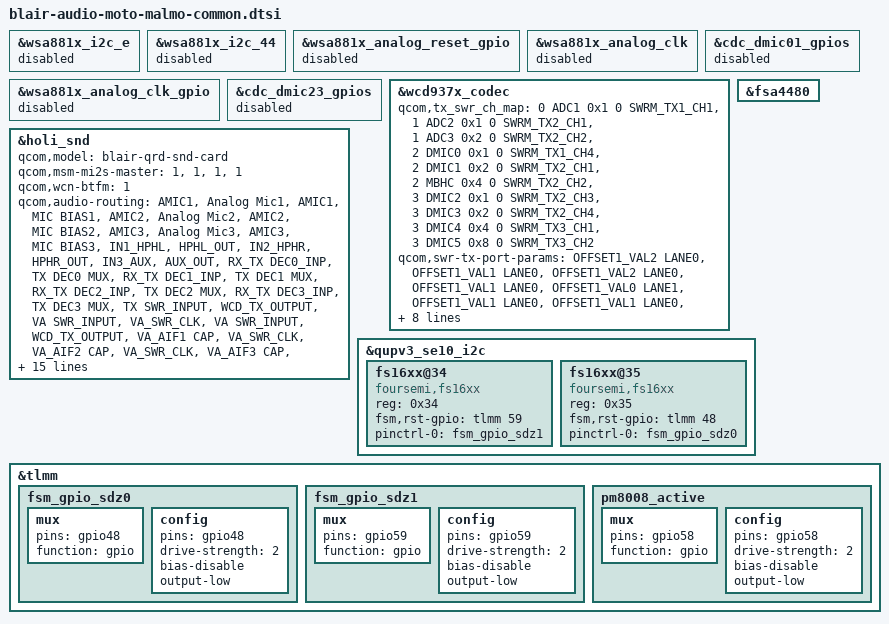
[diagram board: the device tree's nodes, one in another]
/* This is original from blair-audio-qrd.dtsi */
#include "blair-audio-overlay.dtsi"

&wsa881x_i2c_e {
	status = "disabled";
};

&wsa881x_i2c_44 {
	status = "disabled";
};

&wsa881x_analog_reset_gpio {
	status = "disabled";
};

&wsa881x_analog_clk {
	status = "disabled";
};

&wsa881x_analog_clk_gpio {
	status = "disabled";
};

&cdc_dmic01_gpios {
	status = "disabled";
};

&cdc_dmic23_gpios {
	status = "disabled";
};

&wcd937x_codec {
	qcom,tx_swr_ch_map = <0 ADC1 0x1 0 SWRM_TX1_CH1>,
			<1 ADC2 0x1 0 SWRM_TX2_CH1>,
			<1 ADC3 0x2 0 SWRM_TX2_CH2>,
			<2 DMIC0 0x1 0 SWRM_TX1_CH4>,
			<2 DMIC1 0x2 0 SWRM_TX2_CH1>,
			<2 MBHC 0x4 0 SWRM_TX2_CH2>,
			<3 DMIC2 0x1 0 SWRM_TX2_CH3>,
			<3 DMIC3 0x2 0 SWRM_TX2_CH4>,
			<3 DMIC4 0x4 0 SWRM_TX3_CH1>,
			<3 DMIC5 0x8 0 SWRM_TX3_CH2>;
	qcom,swr-tx-port-params =
			<OFFSET1_VAL2 LANE0>, <OFFSET1_VAL1 LANE0>, <OFFSET1_VAL2 LANE0>, <OFFSET1_VAL1 LANE0>,
			<OFFSET1_VAL0 LANE1>, <OFFSET1_VAL1 LANE0>, <OFFSET1_VAL1 LANE0>, <OFFSET1_VAL1 LANE0>,
			<OFFSET1_VAL0 LANE1>, <OFFSET1_VAL2 LANE0>, <OFFSET1_VAL1 LANE0>, <OFFSET1_VAL2 LANE0>,
			<OFFSET1_VAL1 LANE0>, <OFFSET1_VAL1 LANE0>, <OFFSET1_VAL1 LANE0>, <OFFSET1_VAL1 LANE0>;
	qcom,cdc-micbias1-mv = <2500>;
	qcom,cdc-micbias2-mv = <2700>;
	qcom,cdc-micbias3-mv = <2500>;
};

&holi_snd {
	qcom,model = "blair-qrd-snd-card";
	qcom,msm-mi2s-master = <1>, <1>, <1>, <1>;
	qcom,wcn-btfm = <1>;
	qcom,audio-routing =
		"AMIC1", "Analog Mic1",
		"AMIC1", "MIC BIAS1",
		"AMIC2", "Analog Mic2",
		"AMIC2", "MIC BIAS2",
		"AMIC3", "Analog Mic3",
		"AMIC3", "MIC BIAS3",
		"IN1_HPHL", "HPHL_OUT",
		"IN2_HPHR", "HPHR_OUT",
		"IN3_AUX", "AUX_OUT",
		"RX_TX DEC0_INP", "TX DEC0 MUX",
		"RX_TX DEC1_INP", "TX DEC1 MUX",
		"RX_TX DEC2_INP", "TX DEC2 MUX",
		"RX_TX DEC3_INP", "TX DEC3 MUX",
		"TX SWR_INPUT", "WCD_TX_OUTPUT",
		"VA SWR_INPUT", "VA_SWR_CLK",
		"VA SWR_INPUT", "WCD_TX_OUTPUT",
		"VA_AIF1 CAP", "VA_SWR_CLK",
		"VA_AIF2 CAP", "VA_SWR_CLK",
		"VA_AIF3 CAP", "VA_SWR_CLK";

	qcom,msm-mbhc-usbc-audio-supported = <1>;
	qcom,msm-mbhc-hphl-swh = <0>;
	qcom,msm-mbhc-gnd-swh = <0>;

	/delete-property/ qcom,cdc-dmic01-gpios;
	/delete-property/ qcom,cdc-dmic23-gpios;

	nvmem-cells = <&adsp_variant>;
	nvmem-cell-names = "adsp_variant";

	asoc-codec  = <&stub_codec>, <&bolero_cdc>,
		  <&wcd937x_codec>;
	asoc-codec-names = "msm-stub-codec.1", "bolero-codec",
			   "wcd937x_codec";

	qcom,wsa-max-devs = <0>;

	qcom,msm_audio_ssr_devs = <&audio_gpr>, <&lpi_tlmm>,
								<&bolero_cdc>;

	fsa4480-i2c-handle = <&fsa4480>;
	qcom,hac_enable = <&tlmm 58 0>;
};

&fsa4480{
	status = "okay";
};

&qupv3_se10_i2c {
        status = "okay";
	fs16xx@34 {
		status = "ok";
		compatible = "foursemi,fs16xx";
		reg = <0x34>;
		fsm,rst-gpio = <&tlmm 59 0>;
		pinctrl-names = "fsm_sdz_default";
		pinctrl-0 = <&fsm_gpio_sdz1>;
	};
	fs16xx@35 {
		status = "ok";
		compatible = "foursemi,fs16xx";
		reg = <0x35>;
		fsm,rst-gpio = <&tlmm 48 0>;
		pinctrl-names = "fsm_sdz_default";
		pinctrl-0 = <&fsm_gpio_sdz0>;
	};
};

&tlmm {
	fsm_gpio_sdz0:fsm_gpio_sdz0{
		mux{
			pins = "gpio48";
			function = "gpio";
		};
		config{
			pins = "gpio48";
			drive-strength = <2>;
			bias-disable;
			output-low;
		};
	};
	fsm_gpio_sdz1:fsm_gpio_sdz1{
		mux{
			pins = "gpio59";
			function = "gpio";
		};
		config{
			pins = "gpio59";
			drive-strength = <2>;
			bias-disable;
			output-low;
		};
	};
	pm8008_active: pm8008_active {
		mux{
			pins = "gpio58";
			function = "gpio";
		};
		config{
			pins = "gpio58";
			drive-strength = <2>;
			bias-disable;
			output-low;
		};
        };
};
